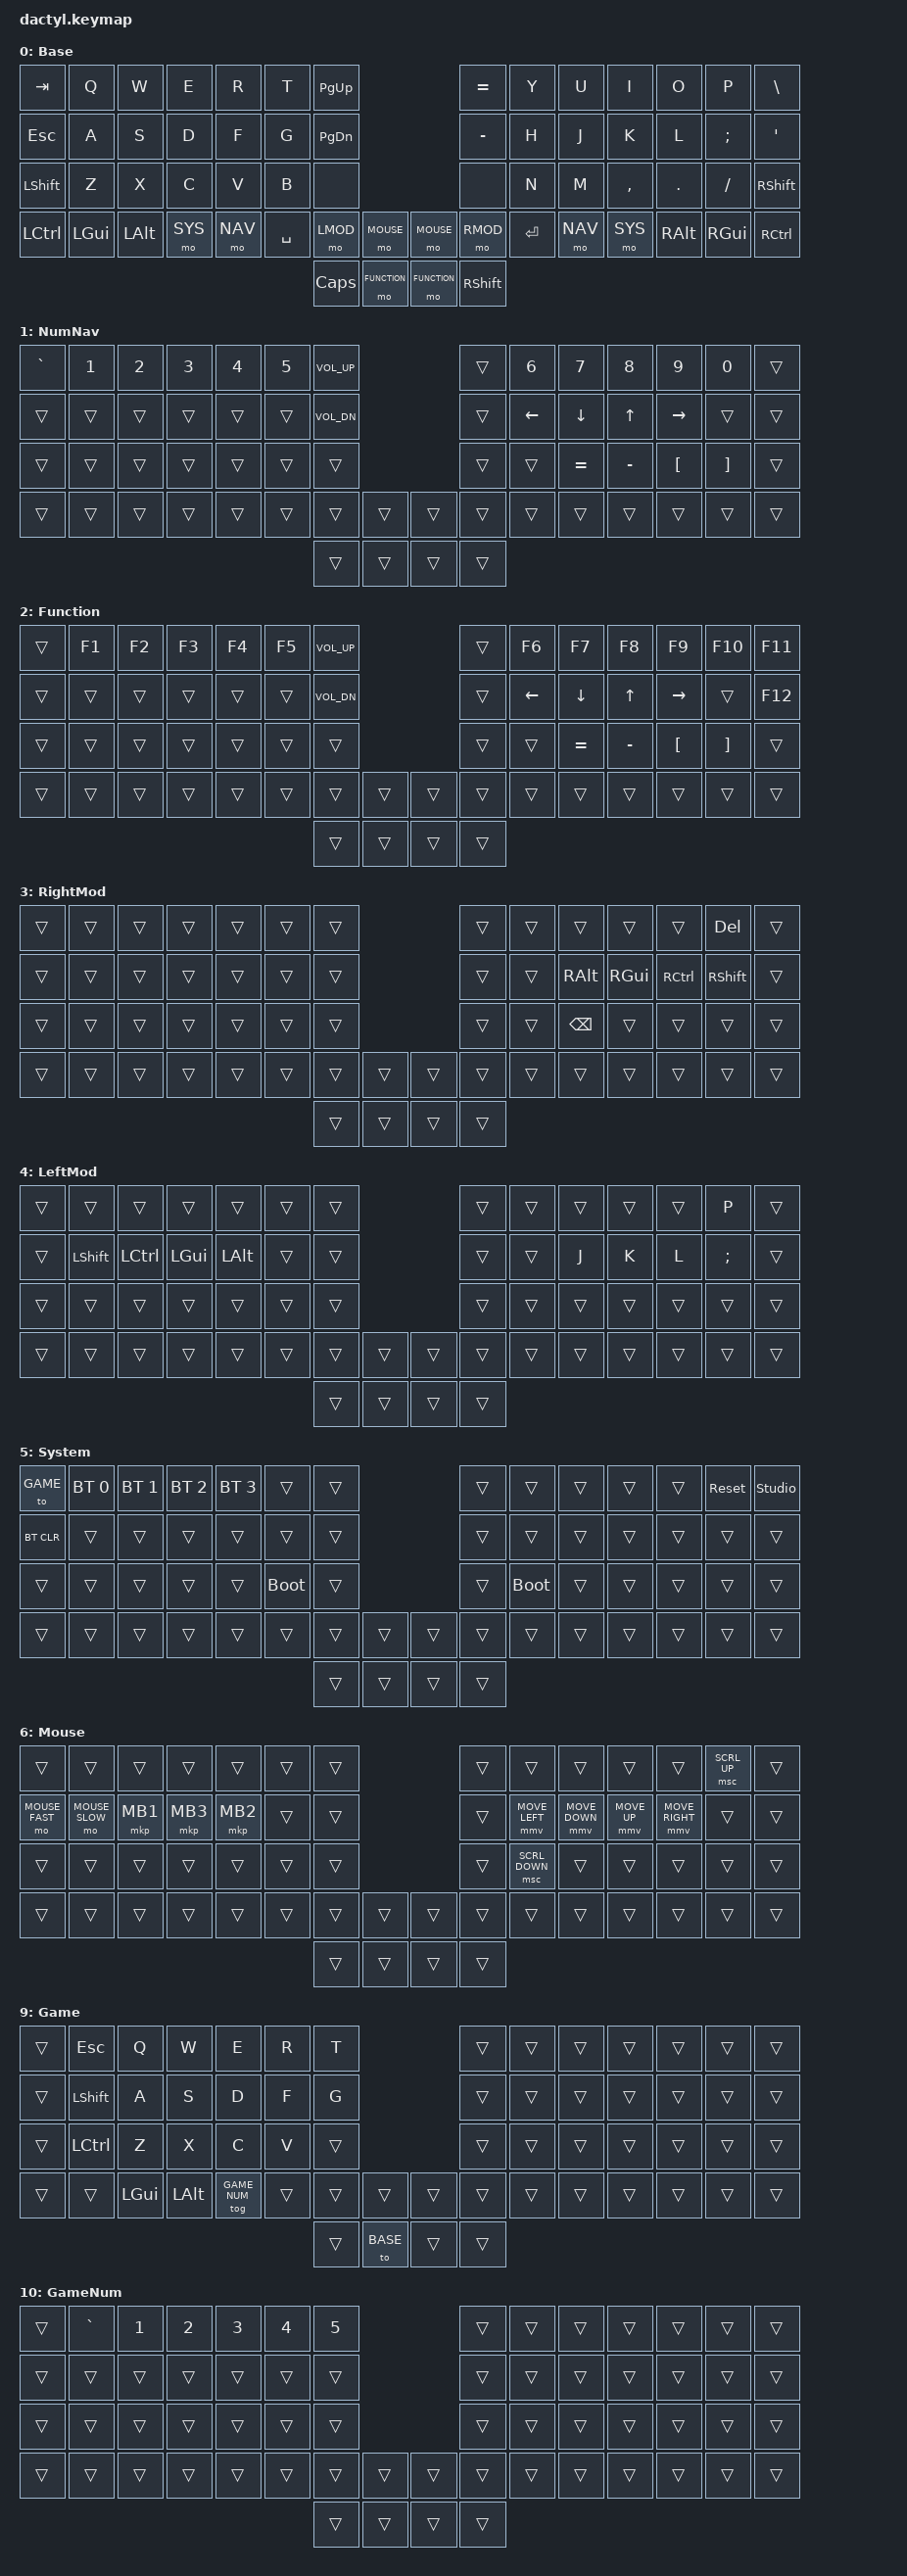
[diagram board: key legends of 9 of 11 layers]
/*
 * Copyright (c) 2020 The ZMK Contributors
 *
 * SPDX-License-Identifier: MIT
 */

// Scroll step for SCRL_UP/SCRL_DOWN; must come before pointing.h is included.
// Moves use the stock MOVE_* step of 600.
#define ZMK_POINTING_DEFAULT_SCRL_VAL 12

#include <behaviors.dtsi>
#include <behaviors/mouse_keys.dtsi>
#include <dt-bindings/zmk/bt.h>
#include <dt-bindings/zmk/keys.h>
#include <dt-bindings/zmk/pointing.h>
#include <input/processors.dtsi>

#define BASE       0
#define NAV        1
#define FUNCTION   2
#define RMOD       3
#define LMOD       4
#define SYS        5
#define MOUSE      6
#define MOUSE_SLOW 7
#define MOUSE_FAST 8
#define GAME       9
#define GAME_NUM   10

// A layer that passes every key through to the one below. MouseSlow and
// MouseFast only exist to switch the mouse speed overrides below.
#define T7 &trans &trans &trans &trans &trans &trans &trans
#define TRANSPARENT_LAYER T7 T7 T7 T7 T7 T7 T7 T7 &trans &trans &trans &trans &trans &trans

&mmv {
    acceleration-exponent = <1>;
    time-to-max-speed-ms = <0>;
    delay-ms = <0>;
    trigger-period-ms = <8>;
};

&msc {
    acceleration-exponent = <1>;
    time-to-max-speed-ms = <0>;
    delay-ms = <0>;
    trigger-period-ms = <8>;
};

// Mouse speed per layer. MouseSlow/MouseFast are held on top of Mouse, and
// the first matching override wins, so they come before the Mouse one.
&mmv_input_listener {
    fast {
        layers = <MOUSE_FAST>;
        input-processors = <&zip_xy_scaler 2 1>;
    };

    fine {
        layers = <MOUSE_SLOW>;
        input-processors = <&zip_xy_scaler 3 8>;
    };

    normal {
        layers = <MOUSE>;
        input-processors = <&zip_xy_scaler 7 6>;
    };
};

&msc_input_listener {
    fast {
        layers = <MOUSE_FAST>;
        input-processors = <&zip_scroll_scaler 3 2>;
    };

    fine {
        layers = <MOUSE_SLOW>;
        input-processors = <&zip_scroll_scaler 1 2>;
    };
};

/ {
    keymap {
        compatible = "zmk,keymap";

        default_layer {
            display-name = "Base";
            bindings = <
&kp TAB    &kp Q     &kp W     &kp E    &kp R    &kp T      &kp PG_UP                                                 &kp EQUAL  &kp Y      &kp U    &kp I      &kp O     &kp P     &kp BSLH
&kp ESC    &kp A     &kp S     &kp D    &kp F    &kp G      &kp PG_DN                                                 &kp MINUS  &kp H      &kp J    &kp K      &kp L     &kp SEMI  &kp SQT
&kp LSHFT  &kp Z     &kp X     &kp C    &kp V    &kp B      &none                                                     &none      &kp N      &kp M    &kp COMMA  &kp DOT   &kp FSLH  &kp RSHFT
&kp LCTRL  &kp LGUI  &kp LALT  &mo SYS  &mo NAV  &kp SPACE             &mo LMOD  &mo MOUSE      &mo MOUSE  &mo RMOD              &kp ENTER  &mo NAV  &mo SYS    &kp RALT  &kp RGUI  &kp RCTRL
                                                                       &kp CAPS  &mo FUNCTION  &mo FUNCTION  &kp RSHFT
            >;
        };

        modmove {
            display-name = "NumNav";
            bindings = <
&kp GRAVE  &kp N1  &kp N2  &kp N3  &kp N4  &kp N5  &kp C_VOL_UP                                      &trans  &kp N6    &kp N7     &kp N8     &kp N9     &kp N0    &trans
&trans     &trans  &trans  &trans  &trans  &trans  &kp C_VOL_DN                                      &trans  &kp LEFT  &kp DOWN   &kp UP     &kp RIGHT  &trans    &trans
&trans     &trans  &trans  &trans  &trans  &trans  &trans                                            &trans  &trans    &kp EQUAL  &kp MINUS  &kp LBKT   &kp RBKT  &trans
&trans     &trans  &trans  &trans  &trans  &trans                &trans  &trans      &trans  &trans          &trans    &trans     &trans     &trans     &trans    &trans
                                                                 &trans  &trans      &trans  &trans
            >;
        };

        functionlayer {
            display-name = "Function";
            bindings = <
&trans   &kp F1  &kp F2  &kp F3  &kp F4  &kp F5  &kp C_VOL_UP                                      &trans  &kp F6    &kp F7     &kp F8     &kp F9     &kp F10  &kp F11
&trans  &trans  &trans  &trans  &trans  &trans  &kp C_VOL_DN                                      &trans  &kp LEFT  &kp DOWN   &kp UP     &kp RIGHT  &trans   &kp F12
&trans  &trans  &trans  &trans  &trans  &trans  &trans                                            &trans  &trans    &kp EQUAL  &kp MINUS  &kp LBKT   &kp RBKT  &trans
&trans  &trans  &trans  &trans  &trans  &trans                &trans  &trans      &trans  &trans          &trans    &trans     &trans     &trans     &trans    &trans
                                                                 &trans  &trans      &trans  &trans
            >;
        };

        rightmod {
            display-name = "RightMod";
            bindings = <
&trans  &trans  &trans  &trans  &trans  &trans  &trans                                      &trans  &trans  &trans    &trans    &trans     &kp DEL    &trans
&trans  &trans  &trans  &trans  &trans  &trans  &trans                                      &trans  &trans  &kp RALT  &kp RGUI  &kp RCTRL  &kp RSHFT  &trans
&trans  &trans  &trans  &trans  &trans  &trans  &trans                                      &trans  &trans  &kp BSPC  &trans    &trans     &trans     &trans
&trans  &trans  &trans  &trans  &trans  &trans          &trans  &trans      &trans  &trans          &trans  &trans    &trans    &trans     &trans     &trans
                                                        &trans  &trans      &trans  &trans
            >;
        };

        leftmod {
            display-name = "LeftMod";
            bindings = <
&trans  &trans     &trans     &trans    &trans    &trans  &trans                                      &trans  &trans  &trans  &trans  &trans  &kp P     &trans
&trans  &kp LSHFT  &kp LCTRL  &kp LGUI  &kp LALT  &trans  &trans                                      &trans  &trans  &kp J   &kp K   &kp L   &kp SEMI  &trans
&trans  &trans     &trans     &trans    &trans    &trans  &trans                                      &trans  &trans  &trans  &trans  &trans  &trans    &trans
&trans  &trans     &trans     &trans    &trans    &trans          &trans  &trans      &trans  &trans          &trans  &trans  &trans  &trans  &trans    &trans
                                                                  &trans  &trans      &trans  &trans
            >;
        };

        bt {
            display-name = "System";
            bindings = <
&to GAME    &bt BT_SEL 0  &bt BT_SEL 1  &bt BT_SEL 2  &bt BT_SEL 3  &trans       &trans                                      &trans  &trans       &trans  &trans  &trans  &sys_reset  &studio_unlock
&bt BT_CLR  &trans        &trans        &trans        &trans        &trans       &trans                                      &trans  &trans       &trans  &trans  &trans  &trans      &trans
&trans      &trans        &trans        &trans        &trans        &bootloader  &trans                                      &trans  &bootloader  &trans  &trans  &trans  &trans      &trans
&trans      &trans        &trans        &trans        &trans        &trans               &trans  &trans      &trans  &trans          &trans       &trans  &trans  &trans  &trans      &trans
                                                                                         &trans  &trans      &trans  &trans
            >;
        };

        mousedefault {
            display-name = "Mouse";
            bindings = <
&trans          &trans          &trans    &trans    &trans    &trans  &trans                                      &trans  &trans          &trans          &trans        &trans           &msc SCRL_UP  &trans
&mo MOUSE_FAST  &mo MOUSE_SLOW  &mkp MB1  &mkp MB3  &mkp MB2  &trans  &trans                                      &trans  &mmv MOVE_LEFT  &mmv MOVE_DOWN  &mmv MOVE_UP  &mmv MOVE_RIGHT  &trans        &trans
&trans          &trans          &trans    &trans    &trans    &trans  &trans                                      &trans  &msc SCRL_DOWN  &trans          &trans        &trans           &trans        &trans
&trans          &trans          &trans    &trans    &trans    &trans          &trans  &trans      &trans  &trans          &trans          &trans          &trans        &trans           &trans        &trans
                                                                              &trans  &trans      &trans  &trans
            >;
        };

        mouseslow {
            display-name = "MouseSlow";
            bindings = <TRANSPARENT_LAYER>;
        };

        mousefast {
            display-name = "MouseFast";
            bindings = <TRANSPARENT_LAYER>;
        };

        game_layer {
            display-name = "Game";
            bindings = <
&trans  &kp ESC    &kp Q     &kp W     &kp E          &kp R   &kp T                                         &trans  &trans  &trans  &trans  &trans  &trans  &trans
&trans  &kp LSHFT  &kp A     &kp S     &kp D          &kp F   &kp G                                         &trans  &trans  &trans  &trans  &trans  &trans  &trans
&trans  &kp LCTRL  &kp Z     &kp X     &kp C          &kp V   &trans                                        &trans  &trans  &trans  &trans  &trans  &trans  &trans
&trans  &trans     &kp LGUI  &kp LALT  &tog GAME_NUM  &trans          &trans  &trans        &trans  &trans          &trans  &trans  &trans  &trans  &trans  &trans
                                                                      &trans  &to BASE      &trans  &trans
            >;
        };

        game_layer_nums {
            display-name = "GameNum";
            bindings = <
&trans  &kp GRAVE  &kp N1  &kp N2  &kp N3  &kp N4  &kp N5                                      &trans  &trans  &trans  &trans  &trans  &trans  &trans
&trans  &trans     &trans  &trans  &trans  &trans  &trans                                      &trans  &trans  &trans  &trans  &trans  &trans  &trans
&trans  &trans     &trans  &trans  &trans  &trans  &trans                                      &trans  &trans  &trans  &trans  &trans  &trans  &trans
&trans  &trans     &trans  &trans  &trans  &trans          &trans  &trans      &trans  &trans          &trans  &trans  &trans  &trans  &trans  &trans
                                                           &trans  &trans      &trans  &trans
            >;
        };
    };
};
